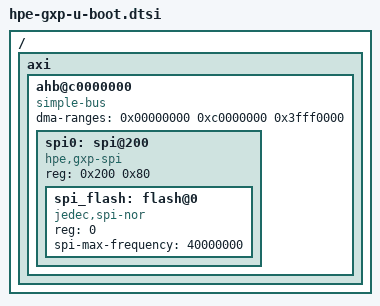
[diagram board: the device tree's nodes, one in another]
// SPDX-License-Identifier: GPL-2.0
/*
 * Device Tree file for HPE GXP
 */

/include/ "hpe-gxp.dtsi"

/ {

	axi {
		
		ahb@c0000000 {
			compatible = "simple-bus";
			#address-cells = <1>;
			#size-cells = <1>;
			dma-ranges = <0x00000000 0xc0000000 0x3fff0000>;
			ranges = <0x00000000 0xc0000000 0x3fff0000>;

			spi0: spi@200 {
				compatible = "hpe,gxp-spi";
				reg = <0x200 0x80>;
				#address-cells = <1>;
				#size-cells = <0>;
				status = "okay";
			
				spi_flash: flash@0 {
					compatible = "jedec,spi-nor";
					reg = <0>;
					spi-max-frequency = <40000000>;
					status = "okay";
				};
			};
		};
	};
};
